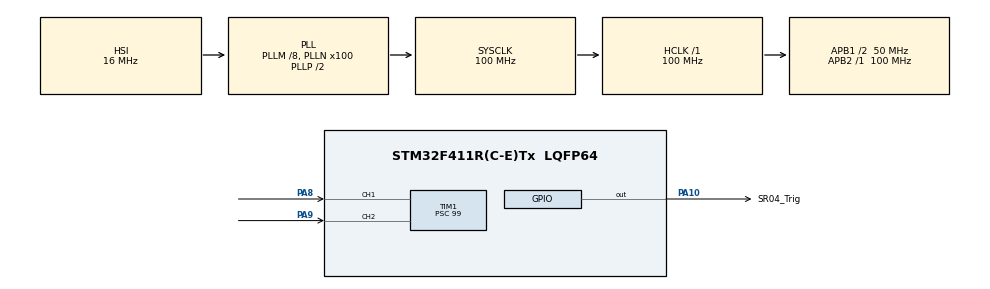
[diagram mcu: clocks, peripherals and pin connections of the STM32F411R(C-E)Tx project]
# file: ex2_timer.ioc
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Dma.Request0=TIM1_CH1
Dma.Request1=TIM1_CH2
Dma.TIM1_CH1.0.Direction=DMA_PERIPH_TO_MEMORY
Dma.TIM1_CH1.0.FIFOMode=DMA_FIFOMODE_DISABLE
Dma.TIM1_CH1.0.Instance=DMA2_Stream1
Dma.TIM1_CH1.0.MemDataAlignment=DMA_MDATAALIGN_HALFWORD
Dma.TIM1_CH1.0.MemInc=DMA_MINC_ENABLE
Dma.TIM1_CH1.0.Mode=DMA_CIRCULAR
Dma.TIM1_CH1.0.PeriphDataAlignment=DMA_PDATAALIGN_HALFWORD
Dma.TIM1_CH1.0.PeriphInc=DMA_PINC_DISABLE
Dma.TIM1_CH1.0.Priority=DMA_PRIORITY_LOW
Dma.TIM1_CH2.1.Direction=DMA_PERIPH_TO_MEMORY
Dma.TIM1_CH2.1.FIFOMode=DMA_FIFOMODE_DISABLE
Dma.TIM1_CH2.1.Instance=DMA2_Stream2
Dma.TIM1_CH2.1.MemDataAlignment=DMA_MDATAALIGN_HALFWORD
Dma.TIM1_CH2.1.MemInc=DMA_MINC_ENABLE
Dma.TIM1_CH2.1.Mode=DMA_CIRCULAR
Dma.TIM1_CH2.1.PeriphDataAlignment=DMA_PDATAALIGN_HALFWORD
Dma.TIM1_CH2.1.PeriphInc=DMA_PINC_DISABLE
Dma.TIM1_CH2.1.Priority=DMA_PRIORITY_LOW
Mcu.Family=STM32F4
Mcu.Name=STM32F411R(C-E)Tx
Mcu.Package=LQFP64
NVIC.DMA2_Stream1_IRQn=true\:0\:0\:false\:false\:true\:false\:true\:true
NVIC.DMA2_Stream2_IRQn=true\:0\:0\:false\:false\:true\:false\:true\:true
NVIC.PriorityGroup=NVIC_PRIORITYGROUP_4
NVIC.TIM1_CC_IRQn=true\:0\:0\:false\:false\:true\:true\:true\:true
PA10.GPIO_Label=SR04_Trig
PA10.GPIO_Speed=GPIO_SPEED_FREQ_VERY_HIGH
PA10.Signal=GPIO_Output
PA13.Mode=Serial_Wire
PA13.Signal=SYS_JTMS-SWDIO
PA14.Mode=Serial_Wire
PA14.Signal=SYS_JTCK-SWCLK
PA8.Signal=S_TIM1_CH1
PA9.Signal=S_TIM1_CH2
PH0\ -\ OSC_IN.Mode=HSE-External-Oscillator
PH0\ -\ OSC_IN.Signal=RCC_OSC_IN
PH1\ -\ OSC_OUT.Mode=HSE-External-Oscillator
PH1\ -\ OSC_OUT.Signal=RCC_OSC_OUT
ProjectManager.HeapSize=0x200
ProjectManager.StackSize=0x400
ProjectManager.TargetToolchain=STM32CubeIDE
RCC.48MHZClocksFreq_Value=50000000
RCC.AHBFreq_Value=100000000
RCC.APB1CLKDivider=RCC_HCLK_DIV2
RCC.APB1Freq_Value=50000000
RCC.APB1TimFreq_Value=100000000
RCC.APB2Freq_Value=100000000
RCC.APB2TimFreq_Value=100000000
RCC.CortexFreq_Value=100000000
RCC.HCLKFreq_Value=100000000
RCC.HSE_VALUE=25000000
RCC.HSI_VALUE=16000000
RCC.LSE_VALUE=32768
RCC.PLLM=8
RCC.PLLN=100
RCC.SYSCLKFreq_VALUE=100000000
RCC.SYSCLKSource=RCC_SYSCLKSOURCE_PLLCLK
RCC.VCOOutputFreq_Value=200000000
SH.S_TIM1_CH1.0=TIM1_CH1,Input_Capture1_from_TI1
SH.S_TIM1_CH2.0=TIM1_CH2,Input_Capture2_from_TI2
TIM1.Channel-Input_Capture1_from_TI1=TIM_CHANNEL_1
TIM1.Channel-Input_Capture2_from_TI2=TIM_CHANNEL_2
TIM1.ICPolarity_CH2=TIM_INPUTCHANNELPOLARITY_FALLING
TIM1.Prescaler=99
TIM3.Prescaler=99
VP_TIM1_VS_ClockSourceINT.Mode=Internal
VP_TIM3_VS_ClockSourceINT.Mode=Internal
board=custom

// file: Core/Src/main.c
/* USER CODE BEGIN Header */
/**
  ******************************************************************************
  * @file           : main.c
  * @brief          : Main program body
  ******************************************************************************
  * @attention
  *
  * Copyright (c) 2025 STMicroelectronics.
  * All rights reserved.
  *
  * This software is licensed under terms that can be found in the LICENSE file
  * in the root directory of this software component.
  * If no LICENSE file comes with this software, it is provided AS-IS.
  *
  ******************************************************************************
  */
/* USER CODE END Header */
#include "main.h"
#include "dma.h"
#include "tim.h"
#include "gpio.h"

/* USER CODE BEGIN PV */
uint16_t valueOnRising[10];
uint16_t valueOnFalling[10];
uint32_t distanceInCm[10];
uint8_t sr04Done_flag = 0;
/* USER CODE END PV */

void SystemClock_Config(void);

/* USER CODE BEGIN 0 */
void HAL_TIM_IC_CaptureCallback(TIM_HandleTypeDef * htim){
	if (htim->Channel == HAL_TIM_ACTIVE_CHANNEL_1){
//		valueOnRising = HAL_TIM_ReadCapturedValue(htim, TIM_CHANNEL_1);
	}
	if (htim->Channel == HAL_TIM_ACTIVE_CHANNEL_2){
//		valueOnRising = HAL_TIM_ReadCapturedValue(htim, TIM_CHANNEL_2);
		sr04Done_flag = 1;
	}
}

void _delay(uint32_t us){
	__HAL_TIM_SET_COUNTER(&htim3, 0);
	HAL_TIM_Base_Start(&htim3);
	while(__HAL_TIM_GET_COUNTER(&htim3) < us);
	HAL_TIM_Base_Stop(&htim3);

}

void SR04_Start(){
	HAL_GPIO_WritePin(SR04_Trig_GPIO_Port, SR04_Trig_Pin, GPIO_PIN_SET);
	HAL_Delay(10);
	HAL_GPIO_WritePin(SR04_Trig_GPIO_Port, SR04_Trig_Pin, GPIO_PIN_RESET);

	__HAL_TIM_SET_COUNTER(&htim1, 0);

}
/* USER CODE END 0 */

int main(void)
{

  /* MCU Configuration--------------------------------------------------------*/

  /* Reset of all peripherals, Initializes the Flash interface and the Systick. */
  HAL_Init();

  /* Configure the system clock */
  SystemClock_Config();

  /* Initialize all configured peripherals */
  MX_GPIO_Init();
  MX_DMA_Init();
  MX_TIM1_Init();
  MX_TIM3_Init();
  /* USER CODE BEGIN 2 */
//  HAL_TIM_IC_Start_IT(&htim1, TIM_CHANNEL_1);
//  HAL_TIM_IC_Start_IT(&htim1, TIM_CHANNEL_2);
  //DMA MODE
  HAL_TIM_IC_Start_DMA(&htim1, TIM_CHANNEL_1, (uint32_t *)valueOnRising, 10);
  HAL_TIM_IC_Start_DMA(&htim1, TIM_CHANNEL_2, (uint32_t *)valueOnFalling, 10);
  /* USER CODE END 2 */

  /* Infinite loop */
  /* USER CODE BEGIN WHILE */
  while (1)
  {
	  SR04_Start();
	  HAL_Delay(100);
	  if(sr04Done_flag == 1){
		  uint32_t diff, i;

		  for(i = 0; i < 10; i++){
			  diff = valueOnFalling[i]- valueOnRising[i];
			  distanceInCm[i] = diff/58;
			  sr04Done_flag = 0;
		  }
	  }
    /* USER CODE END WHILE */

  }
}

void SystemClock_Config(void)
{
  RCC_OscInitTypeDef RCC_OscInitStruct = {0};
  RCC_ClkInitTypeDef RCC_ClkInitStruct = {0};

  /** Configure the main internal regulator output voltage
  */
  __HAL_RCC_PWR_CLK_ENABLE();
  __HAL_PWR_VOLTAGESCALING_CONFIG(PWR_REGULATOR_VOLTAGE_SCALE1);

  /** Initializes the RCC Oscillators according to the specified parameters
  * in the RCC_OscInitTypeDef structure.
  */
  RCC_OscInitStruct.OscillatorType = RCC_OSCILLATORTYPE_HSI;
  RCC_OscInitStruct.HSIState = RCC_HSI_ON;
  RCC_OscInitStruct.HSICalibrationValue = RCC_HSICALIBRATION_DEFAULT;
  RCC_OscInitStruct.PLL.PLLState = RCC_PLL_ON;
  RCC_OscInitStruct.PLL.PLLSource = RCC_PLLSOURCE_HSI;
  RCC_OscInitStruct.PLL.PLLM = 8;
  RCC_OscInitStruct.PLL.PLLN = 100;
  RCC_OscInitStruct.PLL.PLLP = RCC_PLLP_DIV2;
  RCC_OscInitStruct.PLL.PLLQ = 4;
  if (HAL_RCC_OscConfig(&RCC_OscInitStruct) != HAL_OK)
  {
    Error_Handler();
  }

  /** Initializes the CPU, AHB and APB buses clocks
  */
  RCC_ClkInitStruct.ClockType = RCC_CLOCKTYPE_HCLK|RCC_CLOCKTYPE_SYSCLK
                              |RCC_CLOCKTYPE_PCLK1|RCC_CLOCKTYPE_PCLK2;
  RCC_ClkInitStruct.SYSCLKSource = RCC_SYSCLKSOURCE_PLLCLK;
  RCC_ClkInitStruct.AHBCLKDivider = RCC_SYSCLK_DIV1;
  RCC_ClkInitStruct.APB1CLKDivider = RCC_HCLK_DIV2;
  RCC_ClkInitStruct.APB2CLKDivider = RCC_HCLK_DIV1;

  if (HAL_RCC_ClockConfig(&RCC_ClkInitStruct, FLASH_LATENCY_3) != HAL_OK)
  {
    Error_Handler();
  }
}

void Error_Handler(void)
{
  __disable_irq();
  while (1)
  {
  }
}
